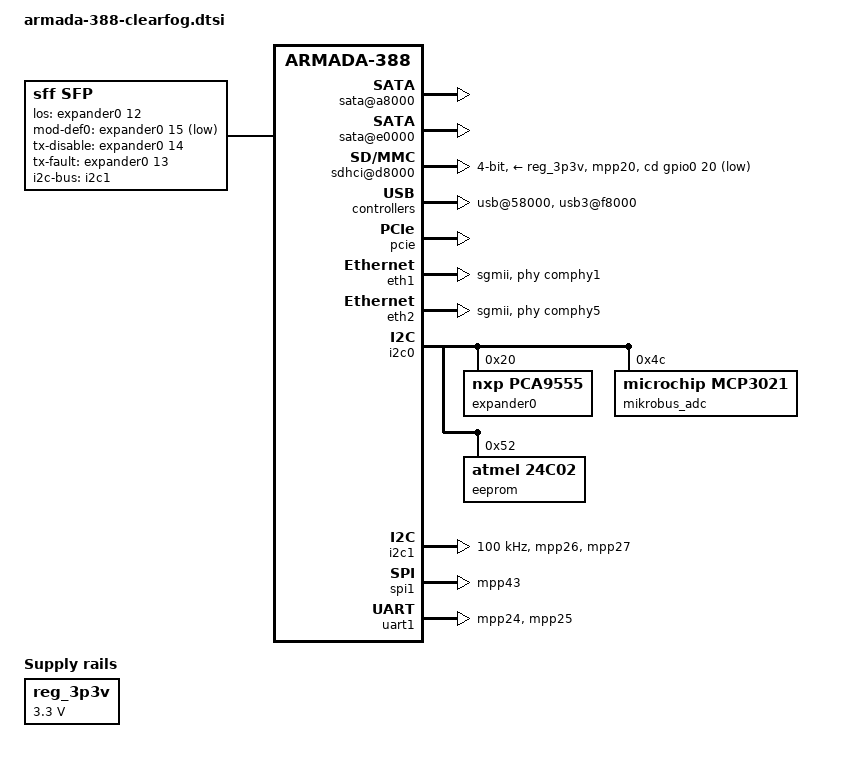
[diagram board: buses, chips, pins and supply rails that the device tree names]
#include "armada-388.dtsi"
#include "armada-38x-solidrun-microsom.dtsi"
/ {
	aliases {
		ethernet1 = &eth0;
		ethernet2 = &eth1;
		ethernet3 = &eth2;
	};
	chosen {
		stdout-path = "serial0:115200n8";
	};
	reg_3p3v: regulator-3p3v {
		compatible = "regulator-fixed";
		regulator-name = "3P3V";
		regulator-min-microvolt = <3300000>;
		regulator-max-microvolt = <3300000>;
		regulator-always-on;
	};
	soc {
		internal-regs {
			sata@a8000 {
				status = "okay";
			};
			sata@e0000 {
				status = "okay";
			};
			sdhci@d8000 {
				bus-width = <4>;
				cd-gpios = <&gpio0 20 GPIO_ACTIVE_LOW>;
				no-1-8-v;
				pinctrl-0 = <&microsom_sdhci_pins
					     &clearfog_sdhci_cd_pins>;
				pinctrl-names = "default";
				status = "okay";
				vmmc-supply = <&reg_3p3v>;
				wp-inverted;
			};
			usb@58000 {
				status = "okay";
			};
			usb3@f8000 {
				status = "okay";
			};
		};
		pcie {
			status = "okay";
			pcie@2,0 {
				reset-gpios = <&expander0 1 GPIO_ACTIVE_LOW>;
				status = "okay";
			};
		};
	};
	sfp: sfp {
		compatible = "sff,sfp";
		i2c-bus = <&i2c1>;
		los-gpio = <&expander0 12 GPIO_ACTIVE_HIGH>;
		mod-def0-gpio = <&expander0 15 GPIO_ACTIVE_LOW>;
		tx-disable-gpio = <&expander0 14 GPIO_ACTIVE_HIGH>;
		tx-fault-gpio = <&expander0 13 GPIO_ACTIVE_HIGH>;
		maximum-power-milliwatt = <2000>;
	};
};
&eth1 {
	bm,pool-long = <2>;
	bm,pool-short = <1>;
	buffer-manager = <&bm>;
	phys = <&comphy1 1>;
	phy-mode = "sgmii";
	status = "okay";
};
&eth2 {
	bm,pool-long = <3>;
	bm,pool-short = <1>;
	buffer-manager = <&bm>;
	managed = "in-band-status";
	phys = <&comphy5 2>;
	phy-mode = "sgmii";
	sfp = <&sfp>;
	status = "okay";
};
&i2c0 {
	expander0: gpio-expander@20 {
		compatible = "nxp,pca9555";
		gpio-controller;
		#gpio-cells = <2>;
		reg = <0x20>;
		pcie1-0-clkreq-hog {
			gpio-hog;
			gpios = <0 GPIO_ACTIVE_LOW>;
			input;
			line-name = "pcie1.0-clkreq";
		};
		pcie1-0-w-disable-hog {
			gpio-hog;
			gpios = <3 GPIO_ACTIVE_LOW>;
			output-low;
			line-name = "pcie1.0-w-disable";
		};
		usb3-ilimit-hog {
			gpio-hog;
			gpios = <5 GPIO_ACTIVE_LOW>;
			input;
			line-name = "usb3-current-limit";
		};
		usb3-power-hog {
			gpio-hog;
			gpios = <6 GPIO_ACTIVE_HIGH>;
			output-high;
			line-name = "usb3-power";
		};
		m2-devslp-hog {
			gpio-hog;
			gpios = <11 GPIO_ACTIVE_HIGH>;
			output-low;
			line-name = "m.2 devslp";
		};
	};
	mikrobus_adc: mcp3021@4c {
		compatible = "microchip,mcp3021";
		reg = <0x4c>;
	};
	eeprom@52 {
		compatible = "atmel,24c02";
		reg = <0x52>;
		pagesize = <16>;
	};
};
&i2c1 {
	clock-frequency = <100000>;
	pinctrl-0 = <&clearfog_i2c1_pins>;
	pinctrl-names = "default";
	status = "okay";
};
&pinctrl {
	clearfog_i2c1_pins: i2c1-pins {
		marvell,pins = "mpp26", "mpp27";
		marvell,function = "i2c1";
	};
	clearfog_sdhci_cd_pins: clearfog-sdhci-cd-pins {
		marvell,pins = "mpp20";
		marvell,function = "gpio";
	};
	mikro_pins: mikro-pins {
		marvell,pins = "mpp22", "mpp29";
		marvell,function = "gpio";
	};
	mikro_spi_pins: mikro-spi-pins {
		marvell,pins = "mpp43";
		marvell,function = "spi1";
	};
	mikro_uart_pins: mikro-uart-pins {
		marvell,pins = "mpp24", "mpp25";
		marvell,function = "ua1";
	};
};
&spi1 {
	pinctrl-0 = <&spi1_pins &mikro_spi_pins>;
	pinctrl-names = "default";
	status = "okay";
};
&uart1 {
	pinctrl-0 = <&mikro_uart_pins>;
	pinctrl-names = "default";
	status = "okay";
};
